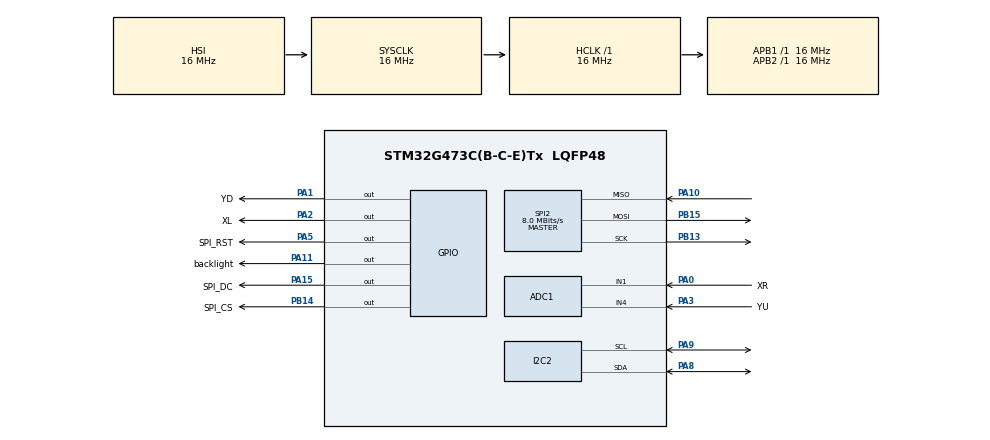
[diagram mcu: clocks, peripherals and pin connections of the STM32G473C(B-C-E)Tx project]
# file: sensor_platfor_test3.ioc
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ADC1.Channel-0\#ChannelRegularConversion=ADC_CHANNEL_1
ADC1.ClockPrescaler=ADC_CLOCK_SYNC_PCLK_DIV1
ADC1.NbrOfConversionFlag=1
ADC1.OffsetNumber-0\#ChannelRegularConversion=ADC_OFFSET_NONE
ADC1.Rank-0\#ChannelRegularConversion=1
ADC1.SamplingTime-0\#ChannelRegularConversion=ADC_SAMPLETIME_640CYCLES_5
ADC1.master=1
FREERTOS.Tasks01=defaultTask,24,128,StartDefaultTask,Default,NULL,Dynamic,NULL,NULL
FREERTOS.configTOTAL_HEAP_SIZE=45000
FREERTOS.configUSE_NEWLIB_REENTRANT=1
I2C2.Timing=0x00503D58
Mcu.Family=STM32G4
Mcu.Name=STM32G473C(B-C-E)Tx
Mcu.Package=LQFP48
NVIC.PriorityGroup=NVIC_PRIORITYGROUP_4
NVIC.TIM6_DAC_IRQn=true\:15\:0\:false\:false\:true\:false\:false\:true\:true
NVIC.TimeBase=TIM6_DAC_IRQn
NVIC.TimeBaseIP=TIM6
PA0.GPIO_Label=XR
PA0.Mode=IN1-Single-Ended
PA0.Signal=ADC1_IN1
PA1.GPIO_Label=YD
PA1.Signal=GPIO_Output
PA10.Mode=Full_Duplex_Master
PA10.Signal=SPI2_MISO
PA11.GPIO_Label=backlight
PA11.Signal=GPIO_Output
PA13.Mode=Serial_Wire
PA13.Signal=SYS_JTMS-SWDIO
PA14.Mode=Serial_Wire
PA14.Signal=SYS_JTCK-SWCLK
PA15.GPIO_Label=SPI_DC
PA15.Signal=GPIO_Output
PA2.GPIO_Label=XL
PA2.Signal=GPIO_Output
PA3.GPIO_Label=YU
PA3.Mode=IN4-Single-Ended
PA3.Signal=ADC1_IN4
PA5.GPIO_Label=SPI_RST
PA5.Signal=GPIO_Output
PA8.Mode=I2C
PA8.Signal=I2C2_SDA
PA9.Mode=I2C
PA9.Signal=I2C2_SCL
PB13.Mode=Full_Duplex_Master
PB13.Signal=SPI2_SCK
PB14.GPIO_Label=SPI_CS
PB14.Signal=GPIO_Output
PB15.Mode=Full_Duplex_Master
PB15.Signal=SPI2_MOSI
ProjectManager.HeapSize=0x200
ProjectManager.StackSize=0x400
ProjectManager.TargetToolchain=STM32CubeIDE
RCC.AHBFreq_Value=16000000
RCC.APB1Freq_Value=16000000
RCC.APB1TimFreq_Value=16000000
RCC.APB2Freq_Value=16000000
RCC.APB2TimFreq_Value=16000000
RCC.CortexFreq_Value=16000000
RCC.EXTERNAL_CLOCK_VALUE=12288000
RCC.HCLKFreq_Value=16000000
RCC.HSE_VALUE=8000000
RCC.HSI48_VALUE=48000000
RCC.HSI_VALUE=16000000
RCC.LSE_VALUE=32768
RCC.SYSCLKFreq_VALUE=16000000
RCC.USBFreq_Value=64000000
RCC.VCOOutputFreq_Value=128000000
SPI2.CalculateBaudRate=8.0 MBits/s
SPI2.DataSize=SPI_DATASIZE_8BIT
SPI2.Direction=SPI_DIRECTION_2LINES
SPI2.Mode=SPI_MODE_MASTER
SPI2.VirtualType=VM_MASTER
VP_FREERTOS_VS_CMSIS_V2.Mode=CMSIS_V2
VP_SYS_VS_DBSignals.Mode=DisableDeadBatterySignals
VP_SYS_VS_tim6.Mode=TIM6
board=custom

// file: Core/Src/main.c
/* USER CODE BEGIN Header */
/**
  ******************************************************************************
  * @file           : main.c
  * @brief          : Main program body
  ******************************************************************************
  * @attention
  *
  * Copyright (c) 2026 STMicroelectronics.
  * All rights reserved.
  *
  * This software is licensed under terms that can be found in the LICENSE file
  * in the root directory of this software component.
  * If no LICENSE file comes with this software, it is provided AS-IS.
  *
  ******************************************************************************
  */
/* USER CODE END Header */
#include "main.h"
#include "cmsis_os.h"
#include "adc.h"
#include "i2c.h"
#include "spi.h"
#include "gpio.h"

/* USER CODE BEGIN Includes */
#include "myapp.h"
/* USER CODE END Includes */

void SystemClock_Config(void);
void MX_FREERTOS_Init(void);

int main(void)
{

  /* MCU Configuration--------------------------------------------------------*/

  /* Reset of all peripherals, Initializes the Flash interface and the Systick. */
  HAL_Init();

  /* Configure the system clock */
  SystemClock_Config();

  /* Initialize all configured peripherals */
  MX_GPIO_Init();
  MX_SPI2_Init();
  MX_I2C2_Init();
  MX_ADC1_Init();

  /* Init scheduler */
  osKernelInitialize();  /* Call init function for freertos objects (in cmsis_os2.c) */
  MX_FREERTOS_Init();

  /* Start scheduler */
  osKernelStart();

  /* We should never get here as control is now taken by the scheduler */

  /* Infinite loop */
  while (1)
  {

  }
}

void SystemClock_Config(void)
{
  RCC_OscInitTypeDef RCC_OscInitStruct = {0};
  RCC_ClkInitTypeDef RCC_ClkInitStruct = {0};

  /** Configure the main internal regulator output voltage
  */
  HAL_PWREx_ControlVoltageScaling(PWR_REGULATOR_VOLTAGE_SCALE1);

  /** Initializes the RCC Oscillators according to the specified parameters
  * in the RCC_OscInitTypeDef structure.
  */
  RCC_OscInitStruct.OscillatorType = RCC_OSCILLATORTYPE_HSI;
  RCC_OscInitStruct.HSIState = RCC_HSI_ON;
  RCC_OscInitStruct.HSICalibrationValue = RCC_HSICALIBRATION_DEFAULT;
  RCC_OscInitStruct.PLL.PLLState = RCC_PLL_NONE;
  if (HAL_RCC_OscConfig(&RCC_OscInitStruct) != HAL_OK)
  {
    Error_Handler();
  }

  /** Initializes the CPU, AHB and APB buses clocks
  */
  RCC_ClkInitStruct.ClockType = RCC_CLOCKTYPE_HCLK|RCC_CLOCKTYPE_SYSCLK
                              |RCC_CLOCKTYPE_PCLK1|RCC_CLOCKTYPE_PCLK2;
  RCC_ClkInitStruct.SYSCLKSource = RCC_SYSCLKSOURCE_HSI;
  RCC_ClkInitStruct.AHBCLKDivider = RCC_SYSCLK_DIV1;
  RCC_ClkInitStruct.APB1CLKDivider = RCC_HCLK_DIV1;
  RCC_ClkInitStruct.APB2CLKDivider = RCC_HCLK_DIV1;

  if (HAL_RCC_ClockConfig(&RCC_ClkInitStruct, FLASH_LATENCY_0) != HAL_OK)
  {
    Error_Handler();
  }
}

void HAL_TIM_PeriodElapsedCallback(TIM_HandleTypeDef *htim)
{
  if (htim->Instance == TIM6)
  {
    HAL_IncTick();
  }
}

void Error_Handler(void)
{
  __disable_irq();
  while (1)
  {
  }
}

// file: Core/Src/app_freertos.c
/* USER CODE BEGIN Header */
/**
  ******************************************************************************
  * File Name          : app_freertos.c
  * Description        : Code for freertos applications
  ******************************************************************************
  * @attention
  *
  * Copyright (c) 2026 STMicroelectronics.
  * All rights reserved.
  *
  * This software is licensed under terms that can be found in the LICENSE file
  * in the root directory of this software component.
  * If no LICENSE file comes with this software, it is provided AS-IS.
  *
  ******************************************************************************
  */
/* USER CODE END Header */

#include "FreeRTOS.h"
#include "task.h"
#include "main.h"
#include "cmsis_os.h"

/* USER CODE BEGIN Includes */
#include "myapp.h"
/* USER CODE END Includes */

/* Definitions for defaultTask */
osThreadId_t defaultTaskHandle;
const osThreadAttr_t defaultTask_attributes = {
  .name = "defaultTask",
  .priority = (osPriority_t) osPriorityNormal,
  .stack_size = 128 * 4
};

void StartDefaultTask(void *argument);

void MX_FREERTOS_Init(void); /* (MISRA C 2004 rule 8.1) */

void MX_FREERTOS_Init(void) {

  /* Create the thread(s) */
  /* creation of defaultTask */
  defaultTaskHandle = osThreadNew(StartDefaultTask, NULL, &defaultTask_attributes);

  /* USER CODE BEGIN RTOS_THREADS */
  /* add threads, ... */
  myapp();
  /* USER CODE END RTOS_THREADS */

}

void StartDefaultTask(void *argument)
{
  for(;;)
  {
    osDelay(1);
  }
}
